# 3066H register map
File version: 1.0
Registers are 32-bit, access per field, reset 0x0 unless marked. A register's access mark holds for its fields unless they carry their own. Offsets are from the block's base; [hi:lo] are bit positions.

## QDM0 — QDM0 peripheral interface
Base 0x14C00000
Same registers: QDM1 0x14C01000, QDM2 0x14C02000, QDM3 0x14C03000
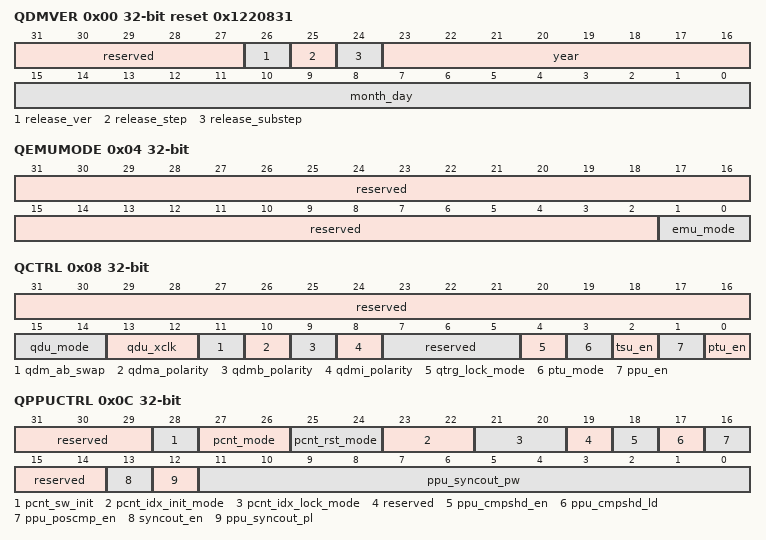
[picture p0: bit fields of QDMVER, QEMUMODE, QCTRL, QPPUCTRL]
0x00 QDMVER ro reset 0x1220831 — QDMVER为QDM Version。QDM版本信息寄存器。
  [31:27] reserved — 保留。
  [26] release_ver — 版本信息。
  [25] release_step — 版本信息。
  [24] release_substep — 版本信息。
  [23:16] year — 年。
  [15:0] month_day — 月日。
0x04 QEMUMODE — QEMUMODE为QDM Emulation Mode。仿真器模式配置寄存器。
  [31:2] reserved ro — 保留。
  [1:0] emu_mode rw — QDM仿真器接入模式。 00：内部计数器（QPOSCNT、QUTMR、QCTMR）当仿真器暂停CPU时，立即停止； 01：QPOSCNT达到最大值复位后，停止；QUTMR当前周期计数完成后，停止；QCTMR在下一个UTTRG后，停止； 10：内部计数器不受仿真器暂停CPU的影响； 11：与10一致。
0x08 QCTRL — QCTRL为QDM Control。QDM控制寄存器。
  [31:16] reserved ro — 保留。
  [15:14] qdu_mode rw — QDM解码模式。 00：正交输入解码模式。输入为正交编码器A，B，Z相信号； 01：脉冲方向输入解码模式。输入为脉冲，方向信号； 10：非标准TYPE1输入解码模式； 11：非标准TYPE2输入解码模式。
  [13:12] qdu_xclk rw — QDM位置脉冲倍频解码。 00：1X倍频。A相上升沿； 01：2X倍频。A相双沿； 10：4X倍频。A相和B相双沿。仅当qdu_mode为正交输入解码模式时才有效，其他模式时是2X倍频； 11：保留。
  [11] qdm_ab_swap rw — QDM A相B相（经过极性选择后）信号交换。 0：不交换； 1：交换。
  [10] qdma_polarity rw — QDM A相输入极性选择。 0：直通； 1：取反。
  [9] qdmb_polarity rw — QDM B相输入极性选择。 0：直通； 1：取反。
  [8] qdmi_polarity rw — QDM Z相（Index）输入极性选择。 0：直通； 1：取反。
  [7:5] reserved ro — 保留。
  [4] qtrg_lock_mode rw — QDM触发锁存模式选择。 0：当总线（CPU/DMA）读QPOSCNT时：锁存位置计数QPOSCNT到QPOSLOCK； 1：当周期触发单元PTU使能且周期触发信号有效时：锁存位置计数QPOSCNT到QPOSLOCK。
  [3] ptu_mode rw — QDM PTU工作模式。 0：周期工作模式。产生周期trigger信号； 1：看门狗工作模式。监控输入信号，用于失速检测。
  [2] tsu_en rw — QDM TSU时间戳单元使能。 0：不使能。TSU停止计数； 1：使能。TSU开始计数。
  [1] ppu_en rw — QDM位置处理单元PPU使能。 0：不使能QDM PPU。PPU停止计数； 1：使能QDM PPU。PPU开始计数。
  [0] ptu_en rw — QDM周期触发单元PTU使能。 0：不使能QDM PTU。PTU停止计数； 1：使能QDM PTU。PTU开始计数。
0x0C QPPUCTRL — QPPUCTRL为QDM Position Process Unit Control，PPU控制寄存器。
  [31:29] reserved ro — 保留。
  [28] pcnt_sw_init rw — 软件初始化位置计数器。 0：软件不初始化位置计数器； 1：软件初始化位置计数器，QPOSCNT=QPOSINIT。软件写1后不会自动清零。
  [27:26] pcnt_mode rw — 位置计数器计数模式。 00：xCLK-xDIR计数模式。对解码后的xCLK，xDIR计数。xDIR为0时，表示逆时针旋转，计数器减计数。反之，增计数； 01：增计数模式。对QDMA增计数； 10：减计数模式。对QDMA减计数； 11：同00。
  [25:24] pcnt_rst_mode rw — QDM位置计数器复位选择。 00：硬件全自动校准（Z相标记点复位）； 01：溢出复位（上溢出后清零，下溢出后置位到qposmax）； 10：硬件单次校准（硬件校准一次后，溢出复位）； 11：单位时间触发（PTU触发）。
  [23:22] pcnt_idx_init_mode rw — QDM Z相（Index）初始化位置计数器模式。 00：不使能； 01：硬件全自动初始化（Z相标记点初始化），将QPOSCNT初始化为QPOSINIT（优先级低于复位）； 10：Z相（Index）上升沿时，将QPOSCNT初始化为QPOSINIT； 11：Z相（Index）下降沿时，将QPOSCNT初始化为QPOSINIT。
  [21:20] pcnt_idx_lock_mode rw — QDM Z相（Index）锁存模式选择。（锁存PPU位置计数器QPOSCNT到QPOSILOCK中）。 00：同11； 01：在Z相(Index)上升沿处锁存； 10：在Z相(Index)下降沿处锁存； 11：在Z相标记点锁存。
  [19] reserved ro — 保留。
  [18] ppu_cmpshd_en rw — QDM位置比较缓存寄存器的使能。 0：不使能缓存寄存器； 1：使能缓存寄存器。
  [17] ppu_cmpshd_ld rw — QDM位置比较缓存寄存器load模式。 0：当QPOSCNT等于0时，把位置比较缓存寄存器load进位置比较active寄存器； 1：当比较成功时，把位置比较缓存寄存器load进位置比较active寄存器。
  [16] ppu_poscmp_en rw — QDM位置比较功能使能。 0：不使能位置比较功能； 1：使能位置比较功能。
  [15:14] reserved ro — 保留。
  [13] syncout_en rw — QDM位置比较同步输出（syncout）使能。 0：不使能同步输出功能； 1：使能同步输出功能。
  [12] ppu_syncout_pl rw — QDM位置比较同步输出（syncout）极性。 0：高有效脉冲输出； 1：低有效脉冲输出。
  [11:0] ppu_syncout_pw rw — QDM位置比较同步输出（syncout）脉宽选择。 0x000：1×4个时钟周期； 0x001：2×4个时钟周期； 0x002：3×4个时钟周期； 0x003：4×4个时钟周期； … 0xFFF：4096×4个时钟周期。
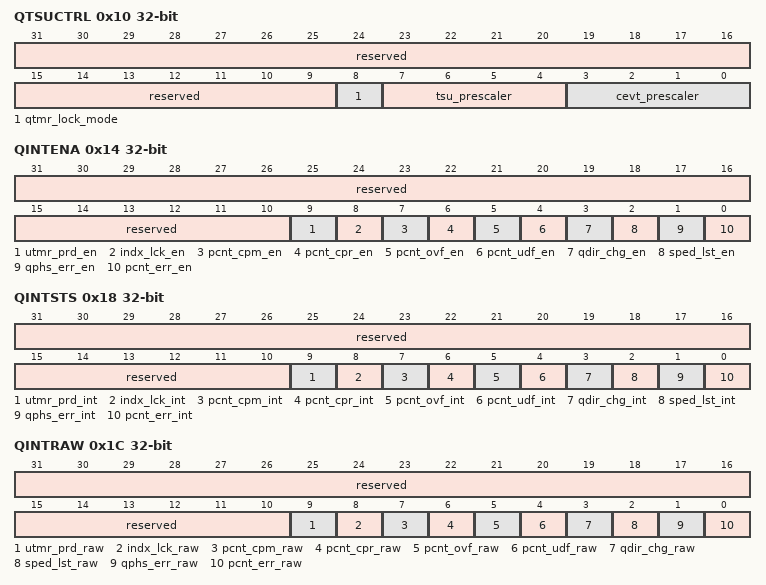
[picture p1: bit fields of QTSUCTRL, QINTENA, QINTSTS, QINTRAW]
0x10 QTSUCTRL — QTSUCTRL为QDM Time Stamp Unit Control，TSU控制寄存器。
  [31:9] reserved ro — 保留。
  [8] qtmr_lock_mode rw — QDM TSU锁存模式。 0：软件读QPOSCNT时，锁存QCTMR到QCTMRLOCK，锁存QCPRD到QCPRDLOCK； 1：单位时间触发信号有效时，锁存QCTMR到QCTMRLOCK，锁存QCPRD到QCPRDLOCK。
  [7:4] tsu_prescaler rw — QDM TSU计时步长选择。 0x0：等于时钟周期； 0x1：2倍时钟周期； 0x2：4倍时钟周期； 0x3：8倍时钟周期； 0x4：16倍时钟周期； 0x5：32倍时钟周期； 0x6：64倍时钟周期； 0x7：128倍时钟周期； 0x8：256倍时钟周期； 其他：256倍时钟周期。
  [3:0] cevt_prescaler rw — QDM捕获事件CEVT分频选择。 0x0：捕获事件频率 = xCLK不分频； 0x1：捕获事件频率 = xCLK的2分频； 0x2：捕获事件频率 = xCLK的4分频； 0x3：捕获事件频率 = xCLK的8分频； 0x4：捕获事件频率 = xCLK的16分频； 0x5：捕获事件频率 = xCLK的32分频； 0x6：捕获事件频率 = xCLK的64分频； 0x7：捕获事件频率 = xCLK的128分频； 0x8：捕获事件频率 = xCLK的256分频； 0x9：捕获事件频率 = xCLK的512分频； 0xA：捕获事件频率 = xCLK的1024分频； 0xB：捕获事件频率 = xCLK的2048分频； 其他：保留。
0x14 QINTENA — QINTENA为QDM Interrupt Enable，QDM中断使能寄存器。
  [31:10] reserved ro — 保留。
  [9] utmr_prd_en rw — QDM PTU周期中断使能。不使能时，即屏蔽相应的中断状态，不影响相应的原始中断。若全部不使能，模块不会上报中断给CPU。 0：不使能； 1：使能。
  [8] indx_lck_en rw — QDM Z相（Index）锁存功能中断使能。 0：不使能； 1：使能。
  [7] pcnt_cpm_en rw — QDM位置比较匹配中断使能。 0：不使能； 1：使能。
  [6] pcnt_cpr_en rw — QDM位置比较就绪中断使能。 0：不使能； 1：使能。
  [5] pcnt_ovf_en rw — QDM位置计数器上溢出中断使能。 0：不使能； 1：使能。
  [4] pcnt_udf_en rw — QDM位置计数器下溢出中断使能。 0：不使能； 1：使能。
  [3] qdir_chg_en rw — QDM正交方向变化中断使能。 0：不使能； 1：使能。
  [2] sped_lst_en rw — QDM失速中断使能。 0：不使能； 1：使能。
  [1] qphs_err_en rw — QDM正交相位错误中断使能。 0：不使能； 1：使能。
  [0] pcnt_err_en rw — QDM位置计数错误中断使能。 0：不使能； 1：使能。
0x18 QINTSTS ro — QINTSTS为QDM Interrupt Status，QDM中断状态寄存器。受中断使能控制。
  [31:10] reserved — 保留。
  [9] utmr_prd_int — QDM PTU周期中断。 0：无中断； 1：有中断。
  [8] indx_lck_int — QDM Z相（Index）锁存功能中断。 0：无中断； 1：有中断。
  [7] pcnt_cpm_int — QDM位置比较匹配中断。 0：无中断； 1：有中断。
  [6] pcnt_cpr_int — QDM位置比较就绪中断。 0：无中断； 1：有中断。
  [5] pcnt_ovf_int — QDM位置计数器上溢出中断。 0：无中断； 1：有中断。
  [4] pcnt_udf_int — QDM位置计数器下溢出中断。 0：无中断； 1：有中断。
  [3] qdir_chg_int — QDM正交方向变化中断。 0：无中断； 1：有中断。
  [2] sped_lst_int — QDM失速中断。 0：无中断； 1：有中断。
  [1] qphs_err_int — QDM正交相位错误中断。 0：无中断； 1：有中断。
  [0] pcnt_err_int — QDM位置计数错误中断。 0：无中断； 1：有中断。
0x1C QINTRAW — QINTRAW为QDM Raw Interrupt，QDM原始中断寄存器。不受中断使能控制。
  [31:10] reserved ro — 保留。
  [9] utmr_prd_raw rw write-clears — QDM PTU周期原始中断。 0：无原始中断； 1：有原始中断。写1清除中断。
  [8] indx_lck_raw rw write-clears — QDM Z相（Index）锁存功能原始中断。 0：无原始中断； 1：有原始中断。写1清除中断。
  [7] pcnt_cpm_raw rw write-clears — QDM位置比较匹配原始中断。 0：无原始中断； 1：有原始中断。写1清除中断。
  [6] pcnt_cpr_raw rw write-clears — QDM位置比较就绪原始中断，当QPOSCMP缓存寄存器载入active寄存器时此bit置高。 0：无原始中断； 1：有原始中断。写1清除中断。
  [5] pcnt_ovf_raw rw write-clears — QDM位置计数器上溢出原始中断。 0：无原始中断； 1：有原始中断。写1清除中断。
  [4] pcnt_udf_raw rw write-clears — QDM位置计数器下溢出原始中断。 0：无原始中断； 1：有原始中断。写1清除中断。
  [3] qdir_chg_raw rw write-clears — QDM正交方向变化原始中断。 0：无原始中断； 1：有原始中断。写1清除中断。
  [2] sped_lst_raw rw write-clears — QDM失速原始中断。当ptu_mode为1时，才可能产生此中断。 0：无原始中断； 1：有原始中断。写1清除中断。
  [1] qphs_err_raw rw write-clears — QDM正交相位错误原始中断。 0：无原始中断； 1：有原始中断。写1清除中断。
  [0] pcnt_err_raw rw write-clears — QDM位置计数错误原始中断。 0：无原始中断； 1：有原始中断。写1清除中断。
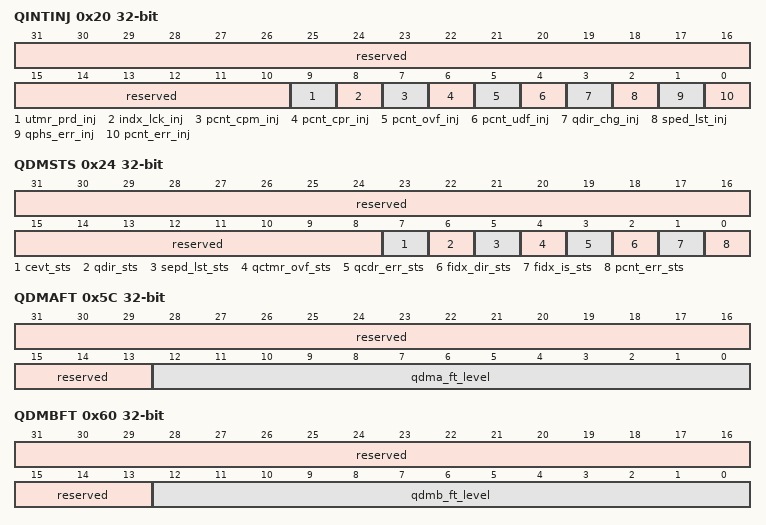
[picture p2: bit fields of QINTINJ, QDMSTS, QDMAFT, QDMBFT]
0x20 QINTINJ — QINTINJ为QDM Interrupt Injection，QDM中断注入寄存器。注入原始中断。
  [31:10] reserved ro — 保留。
  [9] utmr_prd_inj rw write-1-clears — QDM PTU周期中断注入。 0：不注入； 1：注入。
  [8] indx_lck_inj rw write-1-clears — QDM Z相（Index）锁存功能中断注入。 0：不注入； 1：注入。
  [7] pcnt_cpm_inj rw write-1-clears — QDM位置比较匹配中断注入。 0：不注入； 1：注入。
  [6] pcnt_cpr_inj rw write-1-clears — QDM位置比较就绪中断注入。 0：不注入； 1：注入。
  [5] pcnt_ovf_inj rw write-1-clears — QDM位置计数器上溢出中断注入。 0：不注入； 1：注入。
  [4] pcnt_udf_inj rw write-1-clears — QDM位置计数器下溢出中断注入。 0：不注入； 1：注入。
  [3] qdir_chg_inj rw write-1-clears — QDM正交方向变化中断注入。 0：不注入； 1：注入。
  [2] sped_lst_inj rw write-1-clears — QDM失速中断注入。 0：不注入； 1：注入。
  [1] qphs_err_inj rw write-1-clears — QDM正交相位错误中断注入。 0：不注入； 1：注入。
  [0] pcnt_err_inj rw write-1-clears — QDM位置计数错误中断注入。 0：不注入； 1：注入。
0x24 QDMSTS — QDMSTS为QDM Status，QDM状态寄存器。
  [31:8] reserved ro — 保留。
  [7] cevt_sts rw write-clears — QDM捕获事件的状态。 0：没有检测到捕获事件； 1：检测到捕获事件。写1清零。
  [6] qdir_sts ro — QDM正交方向状态（实时值）。 0：逆时针（xDIR=0）； 1：顺时针（xDIR=1）。
  [5] sepd_lst_sts rw write-clears — QDM PTU watchdog模式计数超出最大值，即失速状态。在QUTMR计数到QUPRD都没有XCLK，触发失速中断。 0：未发生； 1：已发生。写1清零。
  [4] qctmr_ovf_sts rw write-clears — QDM TSU时间计数超出最大值，发生溢出。 0：未发生； 1：已发送。写1清零。
  [3] qcdr_err_sts rw write-clears — QDM捕获方向错误的状态。 0：未发生； 1：邻近捕获事件CEVT之间旋转方向发生了变化。写1清零。
  [2] fidx_dir_sts ro — QDM第一次经过Z相标记点时的方向。 0：逆时针（xDIR=0）； 1：顺时针（xDIR=1）。
  [1] fidx_is_sts rw write-clears — QDM是否第一次经过Z相标记点。 0：未第一次经过Z相标记点； 1：已第一次经过Z相标记点。写1清零。
  [0] pcnt_err_sts ro — QDM位置计数错误状态。当且仅当pcnt_rst_mode为硬件全自动校准模式且pcnt_idx_lock_mode为Z相标记点锁存时，计数错误检查功能有效。每次经过Z相标记点时都会更新QPOSILOCK的值，若该值不等于0且不等于QPOSMAX，则认为位置计数错误。 0：上一次经过Z相标记点时，位置计数没有错误； 1：上一次经过Z相标记点时，位置计数有错误。
0x28 QPOSCNT rw — QPOSCNT为QDM PPU Position Counter Value，QDM PPU位置计数值寄存器。
  [31:0] qposcnt — QDM位置计数值。可读可写，仿真器接入暂停生效后，不可写。
0x2C QPOSINIT rw — QPOSINIT为QDM PPU Position Counter Initialization Value，QDM PPU位置初始化值寄存器。
  [31:0] qposinit — QDM位置初始化值。
0x30 QPOSMAX rw — QPOSMAX为QDM PPU Position Counter Maximum Value，QDM PPU位置计数最大值寄存器。
  [31:0] qposmax — QDM位置计数最大值。
0x34 QPOSCMP rw — QPOSCMP为QDM PPU Position Counter (Shadowed) Compare Value，QDM PPU位置比较值缓存寄存器。
  [31:0] qposcmp — QDM位置比较值，缓存寄存器。
0x38 QPOSILOCK rw — QPOSILOCK为QDM PPU QPOSCNT Index Locked Value，QDM Z相信号锁存值寄存器。配置pcnt_idx_lock_mode可改变锁存模式。
  [31:0] qposilock — QDM位置Z相信号（index）锁存值。 配置pcnt_idx_lock_mode，可改变Z相信号（index）锁存模式。软件可写该寄存器，优先级低于锁存。
0x3C QPOSLOCK rw — QPOSLOCK为QDM PPU QPOSCNT Locked Value，位置单位时间触发/软件锁存值寄存器。配置qtrg_lock_mode，可改变锁存模式。
  [31:0] qposlock — QDM位置单位时间触发/软件锁存值。 配置qtrg_lock_mode，可改变锁存模式。软件可写该寄存器，优先级低于锁存。
0x40 QUTMR rw — QUTMR为QDM PTU Counter Value，PTU的计数值寄存器。配置ptu_mode可改变PTU工作模式。
  [31:0] qutmr — QDM周期计数器（PTU）的计数值。 配置ptu_mode可改变PTU工作模式。可读可写，仿真器接入暂停生效后，不可写。
0x44 QUPRD rw — QUPRD为QDM PTU Period Value，PTU的计数周期寄存器。
  [31:0] quprd — QDM周期计数器（PTU）的计数终值。
0x48 QCTMR rw — QCTMR为QDM TSU Counter Value，TSU时间计数值寄存器。
  [31:0] qctmr — QDM TSU时间计数值。可读可写，仿真器接入暂停生效后，不可写。
0x4C QCMAX rw — QCMAX为QDM TSU Counter Maximum Value，TSU时间计数最大值寄存器。
  [31:0] qcmax — QDM TSU时间计数最大值。
0x50 QCPRD ro — QCPRD为QDM TSU-captured CEVT's Period，邻近的2个的捕获事件CEVT之间的时间计数值寄存器。
  [31:0] qcprd — QDM邻近2个的捕获事件CEVT之间的时间计数值。
0x54 QCTMRLOCK rw — QCTMRLOCK为QCTMR Locked Value，QCTMR锁存值寄存器。
  [31:0] qctmrlock — QDM QCTMR锁存值。 配置qtmr_lock_mode，可改变锁存模式。软件可写该寄存器，优先级低于锁存。
0x58 QCPRDLOCK rw — QCPRDLOCK为QCPRD Locked Value，QCPRD锁存值寄存器。
  [31:0] qcprdlock — QDM QCPRD锁存值。 配置qtmr_lock_mode，可改变锁存模式。软件可写该寄存器，优先级低于锁存。
0x5C QDMAFT — QDMAFT为QDM PHASE A Filter，A相信号滤波寄存器。
  [31:13] reserved ro — 保留。
  [12:0] qdma_ft_level rw — A相信号的滤波等级，滤波宽度qdma_ft_level 个时钟周期。
0x60 QDMBFT — QDMBFT为QDM PHASE B Filter，B相信号滤波寄存器。
  [31:13] reserved ro — 保留。
  [12:0] qdmb_ft_level rw — B相信号的滤波等级，滤波宽度qdmb_ft_level 个时钟周期。
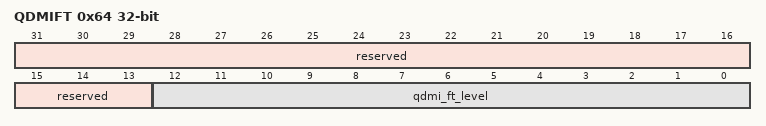
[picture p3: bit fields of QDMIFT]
0x64 QDMIFT — QDMIFT为QDM PHASE Z (Index) Filter，Z相信号滤波寄存器。
  [31:13] reserved ro — 保留。
  [12:0] qdmi_ft_level rw — Z相（lndex）信号的滤波等级，滤波宽度 qdmi_ft_level 个时钟周期。
0x68 QPOSCMPA ro — QPOSCMPA为QDM Position Counter Active Compare Value，位置比较值寄存器，实际用于比较的值。
  [31:0] qposcmpa — QDM位置比较值，实际用于比较的值。
